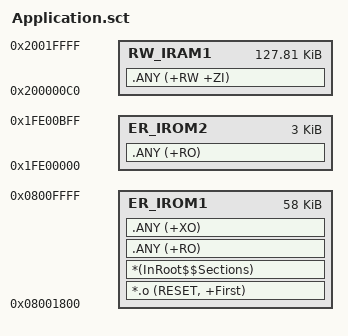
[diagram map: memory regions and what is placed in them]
; *************************************************************
; *** Scatter-Loading Description File generated by uVision ***
; *************************************************************

LR_IROM1 0x08001800 0x0000E800  {    ; load region size_region
  ER_IROM1 0x08001800 0x0000E800  {  ; load address = execution address
   *.o (RESET, +First)
   *(InRoot$$Sections)
   .ANY (+RO)
   .ANY (+XO)
  }
  RW_IRAM1 0x200000C0 0x0001FF40  {  ; RW data
   .ANY (+RW +ZI)
  }
}

LR_IROM2 0x1FE00000 0x00000C00  {
  ER_IROM2 0x1FE00000 0x00000C00  {  ; load address = execution address
   .ANY (+RO)
  }
}
